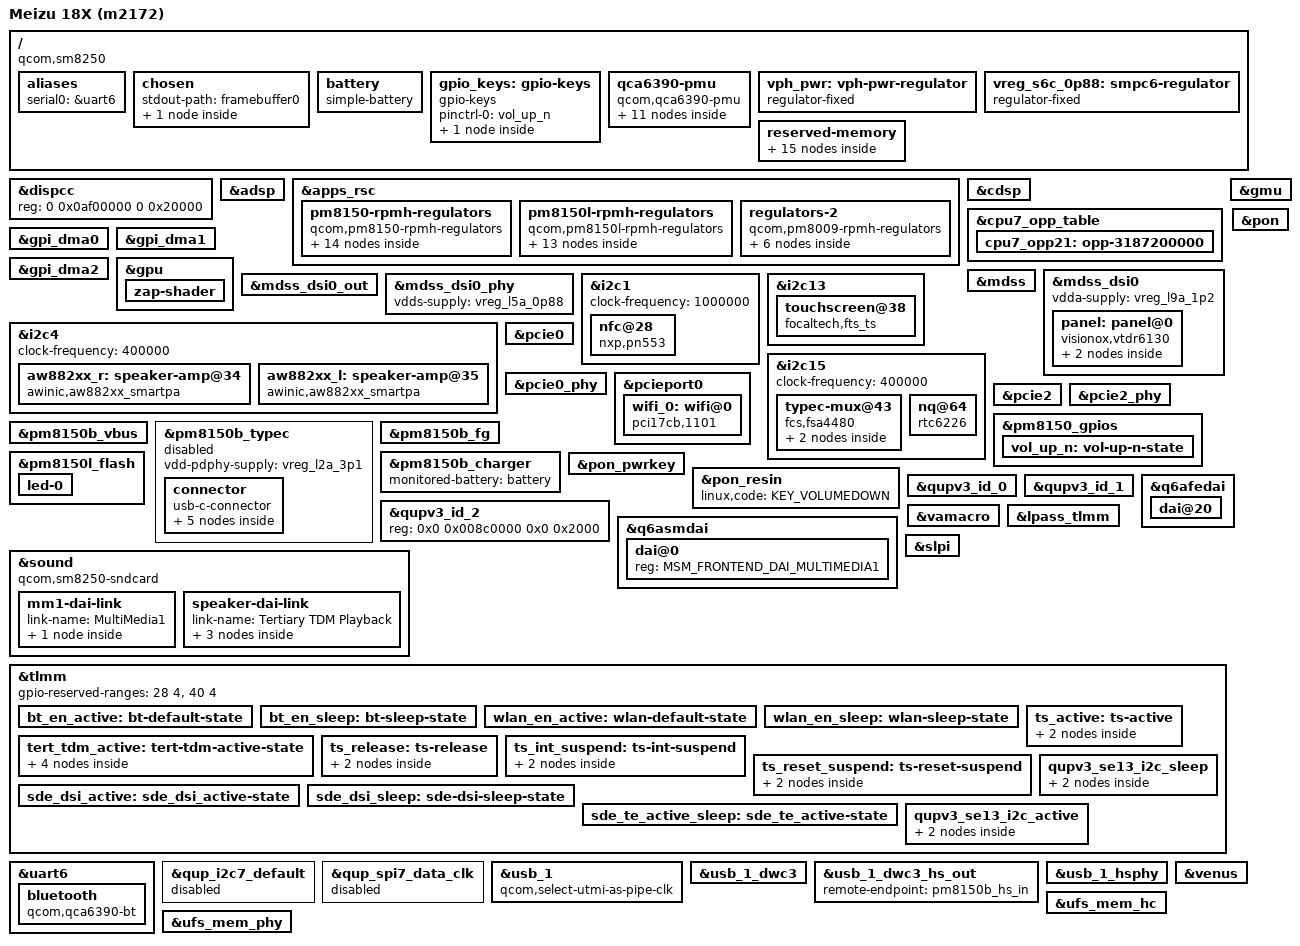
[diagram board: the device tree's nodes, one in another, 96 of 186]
/dts-v1/;

#include <dt-bindings/arm/qcom,ids.h>
#include <dt-bindings/leds/common.h>
#include <dt-bindings/media/video-interfaces.h>
#include <dt-bindings/phy/phy.h>
#include <dt-bindings/regulator/qcom,rpmh-regulator.h>
#include <dt-bindings/sound/qcom,q6afe.h>
#include <dt-bindings/sound/qcom,q6asm.h>
#include <dt-bindings/usb/pd.h>
#include "sm8250.dtsi"
#include "pm8150.dtsi"
#include "pm8150b.dtsi"
#include "pm8150l.dtsi"
#include "pm8009.dtsi"

/delete-node/ &removed_mem;
/delete-node/ &camera_mem;
/delete-node/ &wlan_mem;
/delete-node/ &ipa_fw_mem;
/delete-node/ &ipa_gsi_mem;
/delete-node/ &gpu_mem;
/delete-node/ &npu_mem;
/delete-node/ &video_mem;
/delete-node/ &cvp_mem;
/delete-node/ &cdsp_mem;
/delete-node/ &slpi_mem;
/delete-node/ &adsp_mem;
/delete-node/ &spss_mem;
/delete-node/ &cdsp_secure_heap;

/ {
	model = "Meizu 18X (m2172)";
	compatible = "qcom,sm8250";
	chassis-type = "handset";

	qcom,msm-id = <0x164 0x20001>;
	qcom,board-id = <0x10008 0x00>;

	aliases {
		serial0 = &uart6;
	};

	chosen {
		#address-cells = <2>;
		#size-cells = <2>;
		ranges;
		stdout-path = "framebuffer0";

		framebuffer0: framebuffer@9c000000 {
			compatible = "simple-framebuffer";
			reg = <0x0 0x9c000000 0x0 (1080 * 2400 * 4)>;
			width = <1080>;
			height = <2400>;
			stride = <(1080 * 4)>;
			format = "a8r8g8b8";
			// clocks = <&dispcc DISP_CC_MDSS_AHB_CLK>,
			// 	 <&gcc GCC_DISP_HF_AXI_CLK>,
			// 	 <&gcc GCC_DISP_SF_AXI_CLK>,
			// 	 <&dispcc DISP_CC_MDSS_VSYNC_CLK>,
			// 	 <&dispcc DISP_CC_MDSS_MDP_CLK>,
			// 	 <&dispcc DISP_CC_MDSS_BYTE0_CLK>,
			// 	 <&dispcc DISP_CC_MDSS_BYTE0_INTF_CLK>,
			// 	 <&dispcc DISP_CC_MDSS_PCLK0_CLK>,
			// 	 <&dispcc DISP_CC_MDSS_ESC0_CLK>;
			// power-domains = <&dispcc MDSS_GDSC>;
			// clocks = <&dispcc DISP_CC_MDSS_AHB_CLK>,
			// 	 <&gcc GCC_DISP_HF_AXI_CLK>,
			// 	 <&gcc GCC_DISP_SF_AXI_CLK>,
			// 	 <&dispcc DISP_CC_MDSS_MDP_CLK>;
		};
	};

	battery: battery {
		compatible = "simple-battery";
		charge-full-design-microamp-hours = <4520000>;
		energy-full-design-microwatt-hours = <17500000>;
		voltage-min-design-microvolt = <3400000>;
		voltage-max-design-microvolt = <4450000>;
	};

	gpio_keys: gpio-keys {
		status = "okay";
		compatible = "gpio-keys";

		pinctrl-0 = <&vol_up_n>;
		pinctrl-names = "default";

		key-vol-up {
			label = "Volume Up";
			gpios = <&pm8150_gpios 6 GPIO_ACTIVE_LOW>;
			linux,code = <KEY_VOLUMEUP>;
			debounce-interval = <15>;
			linux,can-disable;
			wakeup-source;
		};
	};

	qca6390-pmu {
		compatible = "qcom,qca6390-pmu";

		pinctrl-names = "default", "sleep";
		pinctrl-0 = <&bt_en_active>, <&wlan_en_active>;
		pinctrl-1 = <&bt_en_sleep>, <&wlan_en_sleep>;

		vddaon-supply = <&vreg_s6a_0p95>;
		vddpmu-supply = <&vreg_s6a_0p95>;
		vddrfa0p95-supply = <&vreg_s6a_0p95>;
		vddrfa1p3-supply = <&vreg_s8c_1p35>;
		vddrfa1p9-supply = <&vreg_s5a_1p9>;
		vddpcie1p3-supply = <&vreg_s8c_1p35>;
		vddpcie1p9-supply = <&vreg_s5a_1p9>;
		vddio-supply = <&vreg_s4a_1p8>;

		wlan-enable-gpios = <&tlmm 20 GPIO_ACTIVE_HIGH>;
		bt-enable-gpios = <&tlmm 21 GPIO_ACTIVE_HIGH>;
		swctrl-gpios = <&tlmm 124 GPIO_ACTIVE_HIGH>;

		regulators {
			vreg_pmu_rfa_cmn: ldo0 {
				regulator-name = "vreg_pmu_rfa_cmn";
			};

			vreg_pmu_aon_0p59: ldo1 {
				regulator-name = "vreg_pmu_aon_0p59";
			};

			vreg_pmu_wlcx_0p8: ldo2 {
				regulator-name = "vreg_pmu_wlcx_0p8";
			};

			vreg_pmu_wlmx_0p85: ldo3 {
				regulator-name = "vreg_pmu_wlmx_0p85";
			};

			vreg_pmu_btcmx_0p85: ldo4 {
				regulator-name = "vreg_pmu_btcmx_0p85";
			};

			vreg_pmu_rfa_0p8: ldo5 {
				regulator-name = "vreg_pmu_rfa_0p8";
			};

			vreg_pmu_rfa_1p2: ldo6 {
				regulator-name = "vreg_pmu_rfa_1p2";
			};

			vreg_pmu_rfa_1p7: ldo7 {
				regulator-name = "vreg_pmu_rfa_1p7";
			};

			vreg_pmu_pcie_0p9: ldo8 {
				regulator-name = "vreg_pmu_pcie_0p9";
			};

			vreg_pmu_pcie_1p8: ldo9 {
				regulator-name = "vreg_pmu_pcie_1p8";
			};
		};
	};

	vph_pwr: vph-pwr-regulator {
		compatible = "regulator-fixed";
		regulator-name = "vph_pwr";
		regulator-min-microvolt = <3700000>;
		regulator-max-microvolt = <3700000>;
	};

	/* S6c is really ebi.lvl but it's there for supply map completeness sake. */
	vreg_s6c_0p88: smpc6-regulator {
		compatible = "regulator-fixed";
		regulator-name = "vreg_s6c_0p88";
		regulator-min-microvolt = <880000>;
		regulator-max-microvolt = <880000>;
		regulator-always-on;
		vin-supply = <&vph_pwr>;
	};

	// refgen_regulator: refgen-regulator@88e7000 {
	// 	compatible = "qcom,sm8250-refgen-regulator";
	// 	regulator-name = "refgen";
	// 	reg = <0 0x88e7000 0 0x84>;
	// };

	reserved-memory {
		// linux,cma {
		// 	linux,cma-default;
		// 	alignment = <0x00 0x400000>;
		// 	alloc-ranges = <0x00 0x00 0x00 0xffffffff>;
		// 	compatible = "shared-dma-pool";
		// 	size = <0x00 0x2000000>;
		// 	reusable;
		// };

		removed_mem: removed_mem@80b00000 {
			reg = <0x0 0x80b00000 0x0 0x9000000>;
			no-map;
		};

		camera_mem: camera_mem@89b00000 {
			reg = <0x0 0x89b00000 0x0 0x500000>;
			no-map;
		};

		wlan_mem: wlan_mem@8a000000 {
			reg = <0x0 0x8a000000 0x0 0x100000>;
			no-map;
		};

		ipa_fw_mem: ipa_fw_mem@8a100000 {
			reg = <0x0 0x8a100000 0x0 0x10000>;
			no-map;
		};

		ipa_gsi_mem: ipa_gsi_mem@8a110000 {
			reg = <0x0 0x8a110000 0x0 0xa000>;
			no-map;
		};

		gpu_mem: gpu_mem@8a11a000 {
			reg = <0x0 0x8a11a000 0x0 0x2000>;
			no-map;
		};

		npu_mem: npu_mem@8a200000 {
			reg = <0x0 0x8a200000 0x0 0x500000>;
			no-map;
		};

		video_mem: video_mem@8a700000 {
			reg = <0x0 0x8a700000 0x0 0x500000>;
			no-map;
		};

		cvp_mem: cvp_mem@8ac00000 {
			reg = <0x0 0x8ac00000 0x0 0x500000>;
			no-map;
		};

		cdsp_mem: cdsp_mem@8b100000 {
			reg = <0x0 0x8b100000 0x0 0x1400000>;
			no-map;
		};

		slpi_mem: slpi_mem@8c500000 {
			reg = <0x00 0x8c500000 0x00 0x1500000>;
			no-map;
		};

		adsp_mem: adsp_mem@8da00000 {
			reg = <0x00 0x8da00000 0x00 0x1d00000>;
			no-map;
		};

		spss_mem: spss_mem@8f700000 {
			reg = <0x00 0x8f700000 0x00 0x100000>;
			no-map;
		};

		cdsp_secure_heap: cdsp_secure_heap@8f800000 {
			reg = <0x00 0x8f800000 0x00 0x4600000>;
			no-map;
		};

		cont_splash_region: cont_splash_region@9c000000 {
			reg = <0x00 0x9c000000 0x00 0x2300000>;
			label = "cont_splash_region";
			no-map;
		};

		// disp_rdump_region@9c000000 {
		// 	reg = <0x00 0x9c000000 0x00 0x800000>;
		// 	label = "disp_rdump_region";
		// 	no-map;
		// };

		// ramoops_region {
		// 	compatible = "ramoops";
		// 	no-map;
		// 	reg = <0x00 0x9f800000 0x00 0x200000>;
		// 	console-size = <0x80000>;
		// 	record-size = <0x80000>;
		// };	
	};

};

&dispcc {
	reg = <0 0x0af00000 0 0x20000>;
	status = "okay";
};

&adsp {
	firmware-name = "qcom/sm8250/meizu/m2172/adsp.mbn";
	status = "okay";
};

&apps_rsc {
	pm8150-rpmh-regulators {
		compatible = "qcom,pm8150-rpmh-regulators";
		qcom,pmic-id = "a";
		status = "okay";

		vdd-s1-supply = <&vph_pwr>;
		vdd-s2-supply = <&vph_pwr>;
		vdd-s3-supply = <&vph_pwr>;
		vdd-s4-supply = <&vph_pwr>;
		vdd-s5-supply = <&vph_pwr>;
		vdd-s6-supply = <&vph_pwr>;
		vdd-s7-supply = <&vph_pwr>;
		vdd-s8-supply = <&vph_pwr>;
		vdd-s9-supply = <&vph_pwr>;
		vdd-s10-supply = <&vph_pwr>;
		vdd-l1-l8-l11-supply = <&vreg_s6c_0p88>;
		vdd-l2-l10-supply = <&vreg_bob>;
		vdd-l3-l4-l5-l18-supply = <&vreg_s6a_0p95>;
		vdd-l6-l9-supply = <&vreg_s8c_1p35>;
		vdd-l7-l12-l14-l15-supply = <&vreg_s5a_1p9>;
		vdd-l13-l16-l17-supply = <&vreg_bob>;

		/* (S1+S2+S3) - cx.lvl (ARC) */

		vreg_s4a_1p8: smps4 {
			regulator-name = "vreg_s4a_1p8";
			regulator-min-microvolt = <1800000>;
			regulator-max-microvolt = <1920000>;
			regulator-initial-mode = <RPMH_REGULATOR_MODE_HPM>;
			regulator-allow-set-load;
			regulator-allowed-modes = <RPMH_REGULATOR_MODE_LPM
						   RPMH_REGULATOR_MODE_HPM>;

		};

		vreg_s5a_1p9: smps5 {
			regulator-name = "vreg_s5a_1p9";
			regulator-min-microvolt = <1900000>;
			regulator-max-microvolt = <2040000>;
			regulator-initial-mode = <RPMH_REGULATOR_MODE_HPM>;
		};

		vreg_s6a_0p95: smps6 {
			regulator-name = "vreg_s6a_0p95";
			regulator-min-microvolt = <950000>;
			regulator-max-microvolt = <1128000>;
			regulator-initial-mode = <RPMH_REGULATOR_MODE_HPM>;
		};

		vreg_l2a_3p1: ldo2 {
			regulator-name = "vreg_l2a_3p1";
			regulator-min-microvolt = <3072000>;
			regulator-max-microvolt = <3072000>;
			regulator-initial-mode = <RPMH_REGULATOR_MODE_HPM>;
		};

		vreg_l3a_0p9: ldo3 {
			regulator-name = "vreg_l3a_0p9";
			regulator-min-microvolt = <928000>;
			regulator-max-microvolt = <932000>;
			regulator-initial-mode = <RPMH_REGULATOR_MODE_HPM>;
		};

		/* L4 - lmx.lvl (ARC) */

		vreg_l5a_0p88: ldo5 {
			regulator-name = "vreg_l5a_0p88";
			regulator-min-microvolt = <880000>;
			regulator-max-microvolt = <880000>;
			regulator-initial-mode = <RPMH_REGULATOR_MODE_HPM>;
		};

		vreg_l6a_1p2: ldo6 {
			regulator-name = "vreg_l6a_1p2";
			regulator-min-microvolt = <1200000>;
			regulator-max-microvolt = <1200000>;
			regulator-initial-mode = <RPMH_REGULATOR_MODE_HPM>;
			regulator-allow-set-load;
			regulator-allowed-modes = <RPMH_REGULATOR_MODE_LPM
						   RPMH_REGULATOR_MODE_HPM>;

		};

		vreg_l9a_1p2: ldo9 {
			regulator-name = "vreg_l9a_1p2";
			regulator-min-microvolt = <1200000>;
			regulator-max-microvolt = <1200000>;
			regulator-initial-mode = <RPMH_REGULATOR_MODE_HPM>;
		};

		vreg_l12a_1p8: ldo12 {
			regulator-name = "vreg_l12a_1p8";
			regulator-min-microvolt = <1800000>;
			regulator-max-microvolt = <1800000>;
			regulator-initial-mode = <RPMH_REGULATOR_MODE_HPM>;
		};

		vreg_l13a_3p3: ldo13 {
			regulator-name = "vreg_l13a_3p3";
			// regulator-min-microvolt = <3304000>;
			// regulator-max-microvolt = <3304000>;
			regulator-min-microvolt = <3008000>;
			regulator-max-microvolt = <3008000>;
			regulator-initial-mode = <RPMH_REGULATOR_MODE_HPM>;
		};

		vreg_l14a_1p88: ldo14 {
			regulator-name = "vreg_l14a_1p88";
			regulator-min-microvolt = <1800000>;
			regulator-max-microvolt = <1880000>;
			regulator-initial-mode = <RPMH_REGULATOR_MODE_HPM>;
		};

		vreg_l16a_3p3: ldo16 {
			regulator-name = "vreg_l16a_3p3";
			regulator-min-microvolt = <3224000>;
			regulator-max-microvolt = <3304000>;
			regulator-initial-mode = <RPMH_REGULATOR_MODE_HPM>;
		};

		vreg_l17a_3p0: ldo17 {
			regulator-name = "vreg_l17a_3p0";
			regulator-min-microvolt = <2496000>;
			regulator-max-microvolt = <3008000>;
			regulator-initial-mode = <RPMH_REGULATOR_MODE_HPM>;
			regulator-allow-set-load;
			regulator-allowed-modes = <RPMH_REGULATOR_MODE_LPM
						   RPMH_REGULATOR_MODE_HPM>;

		};

		vreg_l18a_0p9: ldo18 {
			regulator-name = "vreg_l18a_0p9";
			regulator-min-microvolt = <800000>;
			regulator-max-microvolt = <920000>;
			regulator-initial-mode = <RPMH_REGULATOR_MODE_HPM>;
		};
	};

	/*
	 * Remaining regulators that are not yet supported:
	 * OLEDB: 4925000-8100000
	 * ab: 4600000-6100000
	 * ibb: 800000-5400000
	 */
	pm8150l-rpmh-regulators {
		compatible = "qcom,pm8150l-rpmh-regulators";
		qcom,pmic-id = "c";
		status = "okay";

		vdd-s1-supply = <&vph_pwr>;
		vdd-s2-supply = <&vph_pwr>;
		vdd-s3-supply = <&vph_pwr>;
		vdd-s4-supply = <&vph_pwr>;
		vdd-s5-supply = <&vph_pwr>;
		vdd-s6-supply = <&vph_pwr>;
		vdd-s7-supply = <&vph_pwr>;
		vdd-s8-supply = <&vph_pwr>;
		vdd-l1-l8-supply = <&vreg_s4a_1p8>;
		vdd-l2-l3-supply = <&vreg_s8c_1p35>;
		vdd-l4-l5-l6-supply = <&vreg_bob>;
		vdd-l7-l11-supply = <&vreg_bob>;
		vdd-l9-l10-supply = <&vreg_bob>;
		vdd-bob-supply = <&vph_pwr>;

		vreg_bob: bob {
			regulator-name = "vreg_bob";
			regulator-min-microvolt = <3008000>;
			regulator-max-microvolt = <3960000>;
			regulator-initial-mode = <RPMH_REGULATOR_MODE_AUTO>;
		};

		/*
		 * S1-S6 are ARCs:
		 * (S1+S2) - gfx.lvl,
		 * S3 - mx.lvl,
		 * (S4+S5) - mmcx.lvl,
		 * S6 - ebi.lvl
		 */

		vreg_s7c_0p35: smps7 {
			regulator-name = "vreg_s7c_0p35";
			regulator-min-microvolt = <348000>;
			regulator-max-microvolt = <1000000>;
			regulator-initial-mode = <RPMH_REGULATOR_MODE_HPM>;
		};

		vreg_s8c_1p35: smps8 {
			regulator-name = "vreg_s8c_1p35";
			regulator-min-microvolt = <1350000>;
			regulator-max-microvolt = <1400000>;
			regulator-initial-mode = <RPMH_REGULATOR_MODE_HPM>;
		};

		vreg_l1c_1p8: ldo1 {
			regulator-name = "vreg_l1c_1p8";
			regulator-min-microvolt = <1800000>;
			regulator-max-microvolt = <1800000>;
			regulator-initial-mode = <RPMH_REGULATOR_MODE_HPM>;
		};

		vreg_l2c_1p3: ldo2 {
			regulator-name = "vreg_l2c_1p8";
			regulator-min-microvolt = <1200000>;
			regulator-max-microvolt = <1304000>;
			regulator-initial-mode = <RPMH_REGULATOR_MODE_HPM>;
		};

		vreg_l3c_1p2: ldo3 {
			regulator-name = "vreg_l3c_1p2";
			regulator-min-microvolt = <800000>;
			regulator-max-microvolt = <1200000>;
			regulator-initial-mode = <RPMH_REGULATOR_MODE_HPM>;
		};

		vreg_l5c_1p8: ldo5 {
			regulator-name = "vreg_l5c_1p8";
			regulator-min-microvolt = <1800000>;
			regulator-max-microvolt = <2800000>;
			regulator-initial-mode = <RPMH_REGULATOR_MODE_HPM>;
		};

		vreg_l6c_2p9: ldo6 {
			regulator-name = "vreg_l6c_2p9";
			regulator-min-microvolt = <1800000>;
			regulator-max-microvolt = <2960000>;
			regulator-initial-mode = <RPMH_REGULATOR_MODE_HPM>;
			regulator-allow-set-load;
			regulator-allowed-modes = <RPMH_REGULATOR_MODE_LPM
						   RPMH_REGULATOR_MODE_HPM>;

		};

		vreg_l7c_2p85: ldo7 {
			regulator-name = "vreg_l7c_2p85";
			regulator-min-microvolt = <2856000>;
			regulator-max-microvolt = <3104000>;
			regulator-initial-mode = <RPMH_REGULATOR_MODE_HPM>;
		};

		vreg_l8c_1p8: ldo8 {
			regulator-name = "vreg_l8c_1p8";
			regulator-min-microvolt = <1800000>;
			regulator-max-microvolt = <1800000>;
			regulator-initial-mode = <RPMH_REGULATOR_MODE_HPM>;
		};

		vreg_l9c_2p9: ldo9 {
			regulator-name = "vreg_l9c_2p9";
			regulator-min-microvolt = <2704000>;
			regulator-max-microvolt = <2960000>;
			regulator-initial-mode = <RPMH_REGULATOR_MODE_HPM>;
			regulator-allow-set-load;
			regulator-allowed-modes = <RPMH_REGULATOR_MODE_LPM
						   RPMH_REGULATOR_MODE_HPM>;

		};

		vreg_l10c_3p0: ldo10 {
			regulator-name = "vreg_l10c_303";
			regulator-min-microvolt = <3000000>;
			regulator-max-microvolt = <3312000>;
			regulator-initial-mode = <RPMH_REGULATOR_MODE_HPM>;
		};

		vreg_l11c_3p0: ldo11 {
			regulator-name = "vreg_l11c_3p0";
			regulator-min-microvolt = <3000000>;
			regulator-max-microvolt = <3314000>;
			regulator-initial-mode = <RPMH_REGULATOR_MODE_HPM>;
		};
	};

	regulators-2 {
		compatible = "qcom,pm8009-rpmh-regulators";
		qcom,pmic-id = "f";
		status = "okay";

		vdd-s1-supply = <&vph_pwr>;
		vdd-s2-supply = <&vreg_bob>;
		vdd-l2-supply = <&vreg_s8c_1p35>;
		vdd-l5-l6-supply = <&vreg_bob>;
		vdd-l7-supply = <&vreg_s4a_1p8>;

		vreg_s1f_1p2: smps1 {
			regulator-name = "vreg_s1f_1p2";
			regulator-min-microvolt = <1200000>;
			regulator-max-microvolt = <1300000>;
			regulator-initial-mode = <RPMH_REGULATOR_MODE_HPM>;
		};

		vreg_s2f_0p5: smps2 {
			regulator-name = "vreg_s2f_0p5";
			regulator-min-microvolt = <512000>;
			regulator-max-microvolt = <1100000>;
			regulator-initial-mode = <RPMH_REGULATOR_MODE_HPM>;
		};

		/* L1 is unused. */

		vreg_l2f_1p3: ldo2 {
			regulator-name = "vreg_l2f_1p3";
			regulator-min-microvolt = <1104000>;
			regulator-max-microvolt = <1104000>;
			regulator-initial-mode = <RPMH_REGULATOR_MODE_HPM>;
		};

		/* L3 & L4 are unused. */

		vreg_l5f_2p8: ldo5 {
			regulator-name = "vreg_l5f_2p85";
			regulator-min-microvolt = <2800000>;
			regulator-max-microvolt = <3000000>;
			regulator-initial-mode = <RPMH_REGULATOR_MODE_HPM>;
		};

		vreg_l6f_2p8: ldo6 {
			regulator-name = "vreg_l6f_2p8";
			regulator-min-microvolt = <2800000>;
			regulator-max-microvolt = <3000000>;
			regulator-initial-mode = <RPMH_REGULATOR_MODE_HPM>;
		};

		vreg_l7f_1p8: ldo7 {
			regulator-name = "vreg_l7f_1p8";
			regulator-min-microvolt = <1800000>;
			regulator-max-microvolt = <1800000>;
			regulator-initial-mode = <RPMH_REGULATOR_MODE_HPM>;
		};
	};
};

&cdsp {
	firmware-name = "qcom/sm8250/meizu/m2172/cdsp.mbn";
	status = "okay";
};

// SD870 additional cpu frequency
&cpu7_opp_table {
	cpu7_opp21: opp-3187200000 {
		opp-hz = /bits/ 64 <3187200000>;
		opp-peak-kBps = <8368000 51609600>;
	};
};

&gmu {
	status = "okay";
};

&gpi_dma0 {
	status = "okay";
};

&gpi_dma1 {
	status = "okay";
};

&gpi_dma2 {
	status = "okay";
};

&gpu {
	status = "okay";
	vdd-supply = <&gpucc GPU_GX_GDSC>;
	vddcx-supply = <&gpucc GPU_CX_GDSC>;

	zap-shader {
		memory-region = <&gpu_mem>;
		firmware-name = "qcom/sm8250/meizu/m2172/a650_zap.mbn";
	};
};

&mdss {
	status = "okay";
};

&mdss_dsi0 {
	vdda-supply = <&vreg_l9a_1p2>;
	// refgen-supply = <&refgen_regulator>;
	status = "okay";

	panel: panel@0 {
		compatible = "visionox,vtdr6130";
		reg = <0>;

		pinctrl-0 = <&sde_dsi_active>, <&sde_te_active_sleep>;
		pinctrl-1 = <&sde_dsi_sleep>, <&sde_te_active_sleep>;
		pinctrl-names = "default", "sleep";

		vddio-supply = <&vreg_l14a_1p88>;
		vci-supply = <&vreg_l11c_3p0>;
		vdd-supply = <&vreg_l6a_1p2>;
		// reset-gpios = <&tlmm 12 GPIO_ACTIVE_LOW>;
		reset-gpios = <&tlmm 128 GPIO_ACTIVE_LOW>;

		port {
			panel_in: endpoint {
				remote-endpoint = <&mdss_dsi0_out>;
			};
		};
	};
};

&mdss_dsi0_out {
	remote-endpoint = <&panel_in>;
	data-lanes = <0 1 2 3>;
};

&mdss_dsi0_phy {
	vdds-supply = <&vreg_l5a_0p88>;
	status = "okay";
};

&i2c1 {
	status = "okay";
	clock-frequency = <1000000>;

	nfc@28 {
		compatible = "nxp,pn553",
			     "nxp,nxp-nci-i2c";
		reg = <0x28>;

		interrupt-parent = <&tlmm>;
		interrupts = <111 IRQ_TYPE_EDGE_RISING>;

		enable-gpios = <&tlmm 83 GPIO_ACTIVE_HIGH>;
		firmware-gpios = <&tlmm 110 GPIO_ACTIVE_HIGH>;
	};
};

&i2c4 {
	status = "okay";
	clock-frequency = <400000>;

	aw882xx_r: speaker-amp@34 {
		status = "okay";
		compatible = "awinic,aw882xx_smartpa";
		reg = <0x34>;
		monitor-flag = <0x01>;

		reset-gpio = <&tlmm 116 GPIO_ACTIVE_HIGH>;
		//irq-gpio = <&tlmm 117 0x2008>;

		sound-channel = <0>;
		sync-flag = <0x00>;

		#sound-dai-cells = <1>;
		aw-cali-mode = "aw_misc";
	};

	aw882xx_l: speaker-amp@35 {
		status = "okay";
		compatible = "awinic,aw882xx_smartpa";
		reg = <0x35>;
		monitor-flag = <0x01>;

		reset-gpio = <&tlmm 115 GPIO_ACTIVE_HIGH>;
		// irq-gpio = <&tlmm 118 0x2008>;

		sound-channel = <1>;
		sync-flag = <0x00>;

		#sound-dai-cells = <1>;
		aw-cali-mode = "aw_misc";
	};
};

&i2c13  {
	status = "okay";
	pinctrl-names = "default", "sleep";
	pinctrl-0 = <&qupv3_se13_i2c_active>;
	pinctrl-1 = <&qupv3_se13_i2c_sleep>;
	qcom,i2c-touch-active = "focaltech,fts_ts";
	clock-names = "se", "m-ahb", "s-ahb";
	clocks = <&gcc GCC_QUPV3_WRAP1_S5_CLK &gcc GCC_QUPV3_WRAP_1_S_AHB_CLK &gcc GCC_QUPV3_WRAP_2_M_AHB_CLK>;
	clock-frequency = <400000>;

	touchscreen@38 {
		compatible = "focaltech,fts_ts";
		reg = <0x38>;
		interrupt-parent = <&tlmm>;
		interrupts = <39 IRQ_TYPE_EDGE_FALLING>;
		vdd-supply = <&vreg_l13a_3p3>;
		vcc_i2c-supply = <&vreg_l1c_1p8>;

		pinctrl-0 = <&ts_active>;
		pinctrl-1 = <&ts_int_suspend &ts_reset_suspend>;
		pinctrl-2 = <&ts_release>;
		pinctrl-names = "pmx_ts_active", "pmx_ts_suspend", "pmx_ts_release";

		focaltech,irq-gpio = <&tlmm 39 IRQ_TYPE_EDGE_FALLING>;
		focaltech,reset-gpio = <&tlmm 38 GPIO_ACTIVE_LOW>;

		focaltech,max-touch-number = <10>;
		focaltech,display-coords = <0 0 1080 2400>;

		// panel = <&panel>;
	};
};

&i2c15 {
	clock-frequency = <400000>;
	status = "okay";

	typec-mux@43 {
		compatible = "fcs,fsa4480";
		reg = <0x43>;

		vcc-supply = <&vreg_bob>;

		mode-switch;
		orientation-switch;

		port {
			fsa4480_sbu_mux: endpoint {
				remote-endpoint = <&pm8150b_typec_sbu_out>;
			};
		};
	};

	nq@64 {
		compatible = "rtc6226";
		reg = <0x64>;
		fmint-gpio = <&tlmm 0x33 GPIO_ACTIVE_HIGH>;
		rtc6226,vio-supply = <&vreg_s4a_1p8>;
		// rtc6226,vio-supply-voltage = <0x1b7740 0x1b7740>;
		rtc6226,vdd-supply = <&vreg_bob>;
		// rtc6226,vdd-supply-voltage = <0x324b00 0x324b00>;

	};
};

&pcie0 {
	status = "okay";
};

&pcie0_phy {
	vdda-phy-supply = <&vreg_l5a_0p88>;
	vdda-pll-supply = <&vreg_l9a_1p2>;
	status = "okay";
};

&pcieport0 {
	wifi_0: wifi@0 {
		compatible = "pci17cb,1101";
		reg = <0x10000 0x0 0x0 0x0 0x0>;

		vddrfacmn-supply = <&vreg_pmu_rfa_cmn>;
		vddaon-supply = <&vreg_pmu_aon_0p59>;
		vddwlcx-supply = <&vreg_pmu_wlcx_0p8>;
		vddwlmx-supply = <&vreg_pmu_wlmx_0p85>;
		vddrfa0p8-supply = <&vreg_pmu_rfa_0p8>;
		vddrfa1p2-supply = <&vreg_pmu_rfa_1p2>;
		vddrfa1p7-supply = <&vreg_pmu_rfa_1p7>;
		vddpcie0p9-supply = <&vreg_pmu_pcie_0p9>;
		vddpcie1p8-supply = <&vreg_pmu_pcie_1p8>;
	};
};

&pcie2 {
	status = "okay";
};

&pcie2_phy {
	vdda-phy-supply = <&vreg_l5a_0p88>;
	vdda-pll-supply = <&vreg_l9a_1p2>;
	status = "okay";
};

&pm8150_gpios {
	vol_up_n: vol-up-n-state {
		pins = "gpio6";
		function = "normal";
		power-source = <1>;
		input-enable;
		bias-pull-up;
	};
};

&pm8150b_vbus {
	regulator-min-microamp = <500000>;
	regulator-max-microamp = <3000000>;
	status = "okay";
};

&pm8150b_typec {
	status = "disabled";

	vdd-pdphy-supply = <&vreg_l2a_3p1>;

	connector {
		compatible = "usb-c-connector";

		power-role = "dual";
		data-role = "dual";
		try-power-role = "sink";
		self-powered;

		op-sink-microwatt = <33000000>;

		source-pdos = <PDO_FIXED(5000, 3000,
					  PDO_FIXED_DUAL_ROLE |
					  PDO_FIXED_USB_COMM |
					  PDO_FIXED_DATA_SWAP)>;

		sink-pdos = <PDO_FIXED(5000, 3000,
					   PDO_FIXED_DUAL_ROLE |
					   PDO_FIXED_USB_COMM |
					   PDO_FIXED_DATA_SWAP)
					   PDO_VAR(5000, 9000, 3500)>;

		ports {
			#address-cells = <1>;
			#size-cells = <0>;

			port@0 {
				reg = <0>;
				pm8150b_hs_in: endpoint {
					remote-endpoint = <&usb_1_dwc3_hs_out>;
				};
			};

			port@1 {
				reg = <1>;

				pm8150b_typec_sbu_out: endpoint {
					remote-endpoint = <&fsa4480_sbu_mux>;
				};
			};
		};
	};
};

&pm8150b_fg {
	status = "okay";
	monitored-battery = <&battery>;
	power-supplies = <&pm8150b_charger>;
};

&pm8150b_charger {
	status = "okay";
	monitored-battery = <&battery>;
};

&pm8150l_flash {
	status = "okay";

	led-0 {
		function = LED_FUNCTION_FLASH;
		color = <LED_COLOR_ID_WHITE>;
		led-sources = <1>;
		led-max-microamp = <300000>;
		flash-max-microamp = <1000000>;
		flash-max-timeout-us = <1280000>;
	};
};

&pon {
	mode-bootloader = <0x2>;
	mode-recovery = <0x1>;
};

&pon_pwrkey {
	status = "okay";
};

&pon_resin {
	linux,code = <KEY_VOLUMEDOWN>;
	status = "okay";
};

&qupv3_id_0 {
	status = "okay";
};

&qupv3_id_1 {
	status = "okay";
};

&qupv3_id_2 {
	reg = <0x0 0x008c0000 0x0 0x2000>;
	status = "okay";
};

&q6afedai {
	dai@20 {
		// reg = <TERTIARY_TDM_RX_0>;
		// qcom,tdm-sync-mode = <0>;
		// qcom,tdm-sync-src = <1>;
		// qcom,tdm-data-out = <0>;
		// qcom,tdm-invert-sync = <1>;
		// qcom,tdm-data-delay = <1>;
		// qcom,tdm-data-align = <0>;
		reg = <TERTIARY_MI2S_RX>;
		// qcom,tdm-sync-mode = <1>;     /* Sync mode: 1=secondary (for AW88261) */
		// qcom,tdm-sync-src = <1>;      /* Sync source: 1=internal */
		// qcom,tdm-data-out = <0>;      /* Data out: 0=enabled */
		// qcom,tdm-invert-sync = <0>;   /* Don't invert sync for AW88261 */
		// qcom,tdm-data-delay = <1>;    /* 1-bit data delay for proper alignment */
		// qcom,tdm-data-align = <0>;    /* No special alignment needed */
		qcom,sd-lines = <0>;
	};
};

&q6asmdai {
	status = "okay";
	dai@0 {
		reg = <MSM_FRONTEND_DAI_MULTIMEDIA1>;
	};
};

&vamacro {
	status = "okay";
};

&lpass_tlmm {
	status = "okay";
};

&sound {
	compatible = "qcom,sm8250-sndcard";
	model = "meizu-m2172-sndcard";
	pinctrl-names = "default";
	pinctrl-0 = <&tert_mi2s_active>;
	status = "okay";


	mm1-dai-link {
		link-name = "MultiMedia1";

		cpu {
			sound-dai = <&q6asmdai MSM_FRONTEND_DAI_MULTIMEDIA1>;
		};
	};

	speaker-dai-link {
		link-name = "Tertiary TDM Playback";
		// no-pcm;

		cpu {
			sound-dai = <&q6afedai TERTIARY_MI2S_RX>;
		};

		platform {
			sound-dai = <&q6routing>;
		};

		codec {
			sound-dai = <&aw882xx_r 0>, <&aw882xx_l 0>;
		};
	};
};

&slpi {
	firmware-name = "qcom/sm8250/meizu/m2172/slpi.mbn";
	status = "okay";
};

&tlmm {
	// reg = <0 0x0f000000 0 0x1000000>;
	gpio-reserved-ranges = <28 4>, <40 4>;
	status = "okay";

	bt_en_active: bt-default-state {
		pins = "gpio21";
		function = "gpio";
		drive-strength = <16>;
		output-high;
		bias-pull-up;
	};

	bt_en_sleep: bt-sleep-state {
		pins = "gpio21";
		function = "gpio";
		drive-strength = <2>;
		output-low;
		bias-pull-down;
	};

	wlan_en_active: wlan-default-state {
		pins = "gpio20";
		function = "gpio";
		drive-strength = <16>;
		output-high;
		bias-pull-up;
	};

	wlan_en_sleep: wlan-sleep-state {
		pins = "gpio20";
		function = "gpio";
		drive-strength = <2>;
		output-low;
		bias-pull-down;
	};

	tert_tdm_active: tert-tdm-active-state {
		sck-pins {
			pins = "gpio133";
			function = "mi2s2_sck";
			drive-strength = <8>;
			bias-disable;
			output-high;
		};

		din-pins {
			pins = "gpio134";
			function = "mi2s2_data0";
			drive-strength = <8>;
			bias-disable;
		};

		ws-pins {
			pins = "gpio135";
			function = "mi2s2_ws";
			drive-strength = <8>;
			bias-disable;
			output-high;
		};

		dout-pins {
			pins = "gpio137";
			function = "mi2s2_data1";
			drive-strength = <8>;
			bias-disable;
		};
	};

	ts_active: ts-active {
		mux {
			pins = "gpio38", "gpio39";
			function = "gpio";
		};

		config {
			pins = "gpio38", "gpio39";
			drive-strength = <8>;
			bias-pull-up;
		};
	};

	ts_release: ts-release {
		mux {
			pins = "gpio38", "gpio39";
			function = "gpio";
		};
		config {
			pins = "gpio38", "gpio39";
			drive-strength = <2>;
			bias-disable;
		};
	};

	ts_int_suspend: ts-int-suspend {
		mux {
			pins = "gpio39";
			function = "gpio";
		};
		config {
			pins = "gpio39";
			drive-strength = <2>;
			bias-pull-down;
		};
	};

	ts_reset_suspend: ts-reset-suspend {
		mux {
			pins = "gpio38";
			function = "gpio";
		};
		config {
			pins = "gpio38";
			drive-strength = <2>;
			bias-pull-down;
		};
	};

	sde_dsi_active: sde_dsi_active-state {
		pins = "gpio128";
		function = "gpio";
		drive-strength = <8>;
		bias-disable;
	};

	sde_dsi_sleep: sde-dsi-sleep-state {
		pins = "gpio128";
		function = "gpio";
		drive-strength = <2>;
		bias-pull-down;
	};

	sde_te_active_sleep: sde_te_active-state {
		pins = "gpio67";
		function = "mdp_vsync";
		drive-strength = <2>;
		bias-pull-down;
	};

	qupv3_se13_i2c_sleep: qupv3_se13_i2c_sleep {

		mux {
			function = "gpio";
			pins = "gpio36", "gpio37";
		};

		config {
			pins = "gpio36", "gpio37";
			drive-strength = <0x02>;
			bias-no-pull;
		};
	};

	qupv3_se13_i2c_active: qupv3_se13_i2c_active {

		mux {
			function = "qup13";
			pins = "gpio36", "gpio37";
		};

		config {
			pins = "gpio36", "gpio37";
			drive-strength = <0x02>;
			bias-disable;
		};
	};

};

&uart6 {
	status = "okay";

	bluetooth {
		compatible = "qcom,qca6390-bt";

		enable-gpios = <&tlmm 21 GPIO_ACTIVE_HIGH>;
		swctrl-gpios = <&tlmm 124 GPIO_ACTIVE_HIGH>;

		vddrfacmn-supply = <&vreg_pmu_rfa_cmn>;
		vddaon-supply = <&vreg_pmu_aon_0p59>;
		vddbtcmx-supply = <&vreg_pmu_btcmx_0p85>;
		vddrfa0p8-supply = <&vreg_pmu_rfa_0p8>;
		vddrfa1p2-supply = <&vreg_pmu_rfa_1p2>;
		vddrfa1p7-supply = <&vreg_pmu_rfa_1p7>;
	};
};

&qup_i2c7_default {
	status = "disabled";
};

&qup_spi7_data_clk {
	status = "disabled";
};

&usb_1 {
	/* USB 2.0 only */
	qcom,select-utmi-as-pipe-clk;
	status = "okay";
};

&usb_1_dwc3 {
	dr_mode = "otg";
	usb-role-switch;
	maximum-speed = "high-speed";
	/* Remove USB3 phy */
	phys = <&usb_1_hsphy>;
	phy-names = "usb2-phy";
	status = "okay";
};

&usb_1_dwc3_hs_out {
	remote-endpoint = <&pm8150b_hs_in>;
};

&usb_1_hsphy {
	vdda-pll-supply = <&vreg_l5a_0p88>;
	vdda18-supply = <&vreg_l12a_1p8>;
	vdda33-supply = <&vreg_l2a_3p1>;
	status = "okay";
};

&ufs_mem_hc {
	vcc-supply = <&vreg_l17a_3p0>;
	vcc-max-microamp = <800000>;
	vccq-supply = <&vreg_l6a_1p2>;
	vccq-max-microamp = <800000>;
	vccq2-supply = <&vreg_s4a_1p8>;
	vccq2-max-microamp = <800000>;
	status = "okay";
};

&ufs_mem_phy {
	vdda-phy-supply = <&vreg_l5a_0p88>;
	vdda-pll-supply = <&vreg_l9a_1p2>;
	status = "okay";
};

&venus {
	firmware-name = "qcom/sm8250/meizu/m2172/venus.mbn";
	status = "okay";
};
